# TLE985x register map
Vendor: Infineon Technologies AG; Series: MOTIX MCU; File version: 1.6
CPU: CM0 r0p0, little endian, no MPU, no FPU, 2 interrupt priority bits
Registers are 32-bit, read-write, no defined reset value unless marked. A register's access mark holds for its fields unless they carry their own. Offsets are from the block's base; [hi:lo] are bit positions; {n}, {i} and the like mark numbered series; 'fields as' and 'values as' point back to an identical list.

## ADC1
Base 0x40004000
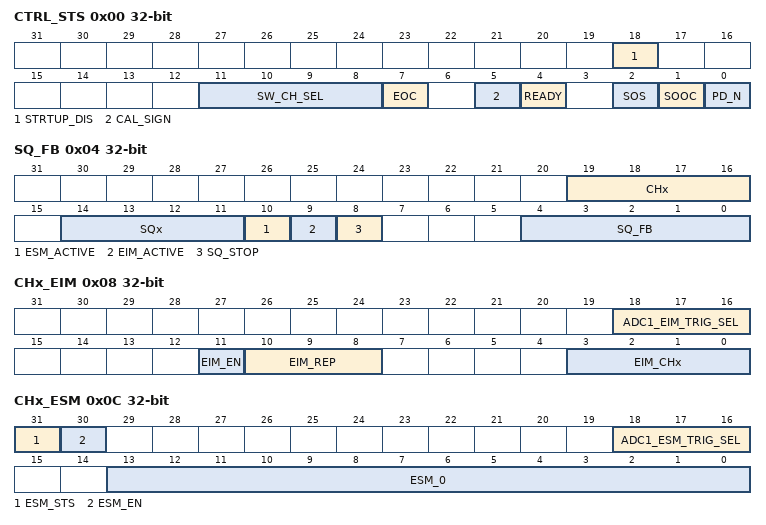
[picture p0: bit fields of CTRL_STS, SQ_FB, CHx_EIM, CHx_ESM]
0x00 CTRL_STS access per field — ADC1 Control and Status Register
  [18] STRTUP_DIS rw — DPP1 Startup Disable
    0=Startup_Enable (DPP1 Startup enabled); 1=Startup_Disable (DPP1 Startup disable)
  [11:8] SW_CH_SEL rw — Channel for software mode
    {v}=CH{v}_EN (Channel {v} enable) (v=0..9); 12=CH12_EN (Channel 12 enable); 13=CH13_EN (Channel 13 enable)
  [7] EOC ro — ADC1 End of Conversion (software mode)
    0=Pending (conversion still running); 1=Finished (conversion has finished)
  [5] CAL_SIGN ro — Output of Comparator to Steer Gain / Offset calibration
  [4] READY ro — HVADC Ready bit
    0=Not_ready (Module in power down or in init phase); 1=Ready (set automatically 5 ADC clock cycles after module is enabled)
  [2] SOS rw — ADC1 Start of Sampling/Conversion (software mode)
    0=Disable (no conversion is started); 1=Enable (conversion is started)
  [1] SOOC rw — ADC1 Start of Offset Calibration (software mode)
    0=Disable (no offset calibration is started); 1=Enable (offset calibration is started)
  [0] PD_N rw — ADC1 Power Down Signal
    0=POWER_DOWN (ADC1 is powered down); 1=ACTIVE (ADC1 is switched on)
0x04 SQ_FB ro — Sequencer Feedback Register
  [19:16] CHx — Current ADC1 Channel
    {v}=CH{v} (Channel {v} enable) (v=0..13)
  [14:11] SQx — Current Active ADC1 Sequence
    {v}=SQ{v} (Sequence {v} enable) (v=0..13)
  [10] ESM_ACTIVE — ADC1 ESM active
    0=not_active (ESM not active); 1=active (ESM active)
  [9] EIM_ACTIVE — ADC1 EIM active
    0=not_active (EIM not active); 1=active (EIM active)
  [8] SQ_STOP — ADC1 Sequencer Stop Signal for DPP
    0=DPP_Running (Postprocessing Sequencer in running mode); 1=DPP_Stopped (Postprocessing Sequencer stopped / Software Mode entered)
  [4:0] SQ_FB — Current Sequence that caused software mode
    {v}=SQ{v} (Sequence {v} enable) (v=0..13); 26=ESM; 28=SUSPEND (SW Mode per Flag)
0x08 CHx_EIM — Channel Setting Bits for Exceptional Interrupt Measurement
  [18:16] ADC1_EIM_TRIG_SEL — Trigger selection for exceptional interrupt measurement (EIM)
    0=NONE; 1=COUT63; 2=GPT12_T6OUT; 3=GPT12_T3OUT; 4=T2 (t2_adc_trigger); 5=T21 (t21_adc_trigger)
  [11] EIM_EN — Exceptional interrupt measurement (EIM) Trigger Event enable
    0=DISABLE (start of EIM disabled); 1=ENABLE (start of IEM enabled)
  [10:8] EIM_REP — Repeat count for exceptional interrupt measurement (EIM)
    0=Continuous Mode; 1=Measurements (2 SOC generated for ADC10); 2=Measurements (4 SOC generated for ADC10); 3=Measurements (8 SOC generated for ADC10); 4=Measurements (16 SOC generated for ADC10); 5=Measurements (32 SOC generated for ADC10); 6=Measurements (64 SOC generated for ADC10); 7=Measurements (128 SOC generated for ADC10)
  [3:0] EIM_CHx — Channel set for exceptional interrupt measurement (EIM)
    values as CTRL_STS.SW_CH_SEL
0x0C CHx_ESM — Channel Setting Bits for Exceptional Sequence Measurement
  [31] ESM_STS — Exceptional Sequence Measurement is finished
    0=not_active (Exceptional Sequence Measurement not done); 1=done (Exceptional Sequence Measurement done)
  [30] ESM_EN — Enable for Exceptional Sequence Measurement Trigger Event
    0=Disable (start of ESM disabled); 1=Enable (start of ESM enabled)
  [18:16] ADC1_ESM_TRIG_SEL — Trigger selection for exceptional sequence measurement (ESM)
    values as CHx_EIM.ADC1_EIM_TRIG_SEL
  [13:0] ESM_0 — Channel Sequence for Exceptional Sequence Measurement (ESM)
    1=CH0_EN (Channel 0 enable); 2=CH1_EN (Channel 1 enable); 4=CH2_EN (Channel 2 enable); 8=CH3_EN (Channel 3 enable); 16=CH4_EN (Channel 4 enable); 32=CH5_EN (Channel 5 enable); 64=CH6_EN (Channel 6 enable); 128=CH7_EN (Channel 7 enable); 0x100=CH8_EN (Channel 8 enable); 0x200=CH9_EN (Channel 9 enable); 0x400=CH10_EN (Channel 10 enable); 0x800=CH11_EN (Channel 11 enable); 0x1000=CH12_EN (Channel 12 enable); 0x2000=CH13_EN (Channel 13 enable)
0x10 MAX_TIME — Maximum Time for Software Mode
  [7:0] MAX_TIME — Maximum Time in Software Mode
    0=min (Software mode is immediately left); 255=max (Software mode is active for 12.75 us)
0x14 CTRL2 — Measurement Unit 1 Control Register 2
  [13:0] CAL_EN — Calibration Enable for Channels 0 to 13
    1=CH0_EN (Channel 0 calibration enable); 2=CH1_EN (Channel 1 calibration enable); 4=CH2_EN (Channel 2 calibration enable); 8=CH3_EN (Channel 3 calibration enable); 16=CH4_EN (Channel 4 calibration enable); 32=CH5_EN (Channel 5 calibration enable); 64=CH6_EN (Channel 6 calibration enable); 128=CH7_EN (Channel 7 calibration enable); 0x100=CH8_EN (Channel 8 calibration enable); 0x200=CH9_EN (Channel 9 calibration enable); 0x400=CH10_EN (Channel 10 calibration enable); 0x800=CH11_EN (Channel 11 calibration enable); 0x1000=CH12_EN (Channel 12 calibration enable); 0x2000=CH13_EN (Channel 13 calibration enable)
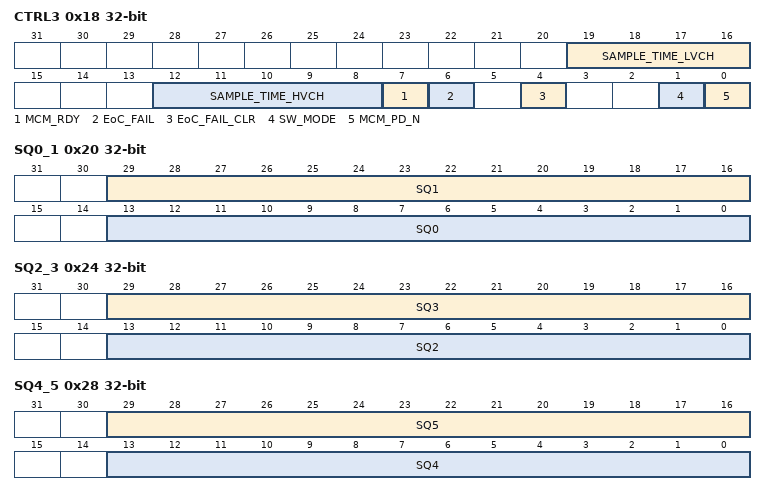
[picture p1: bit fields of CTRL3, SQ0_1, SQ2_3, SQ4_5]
0x18 CTRL3 access per field — Measurement Unit 1 Control Register 3
  [19:16] SAMPLE_TIME_LVCH rw — Sample time of ADC1
    0=ADCCLK4 (4 ADC_CLK clock periods); 1=ADCCLK6 (6 ADC_CLK clock periods); 2=ADCCLK8 (8 ADC_CLK clock periods(default)); 3=ADCCLK10 (10 ADC_CLK clock periods); 4=ADCCLK12 (12 ADC_CLK clock periods); 5=ADCCLK14 (14 ADC_CLK clock periods); 6=ADCCLK16 (16 ADC_CLK clock periods); 7=ADCCLK18 (18 ADC_CLK clock periods); 8=ADCCLK20 (20 ADC_CLK clock periods); 9=ADCCLK22 (22 ADC_CLK clock periods)
  [12:8] SAMPLE_TIME_HVCH rw — Sample time of ADC1
    0=ADCCLK4 (4 ADC_CLK clock periods); 1=ADCCLK6 (6 ADC_CLK clock periods); 2=ADCCLK8 (8 ADC_CLK clock periods); 3=ADCCLK10 (10 ADC_CLK clock periods); 4=ADCCLK12 (12 ADC_CLK clock periods); 5=ADCCLK14 (14 ADC_CLK clock periods); 6=ADCCLK16 (16 ADC_CLK clock periods); 7=ADCCLK18 (18 ADC_CLK clock periods); 8=ADCCLK20 (20 ADC_CLK clock periods); 9=ADCCLK22 (22 ADC_CLK clock periods); 10=ADCCLK24 (24 ADC_CLK clock periods (default)); 11=ADCCLK26 (26 ADC_CLK clock periods); 12=ADCCLK28 (28 ADC_CLK clock periods); 13=ADCCLK30 (30 ADC_CLK clock periods); 14=ADCCLK32 (32 ADC_CLK clock periods); 15=ADCCLK34 (34 ADC_CLK clock periods); 16=ADCCLK36 (36 ADC_CLK clock periods); 17=ADCCLK38 (38 ADC_CLK clock periods); 18=ADCCLK40 (40 ADC_CLK clock periods); 19=ADCCLK42 (42 ADC_CLK clock periods); 20=ADCCLK44 (44 ADC_CLK clock periods); 21=ADCCLK46 (46 ADC_CLK clock periods); 22=ADCCLK48 (48 ADC_CLK clock periods); 23=ADCCLK50 (50 ADC_CLK clock periods); 24=ADCCLK52 (52 ADC_CLK clock periods); 25=ADCCLK54 (54 ADC_CLK clock periods); 26=ADCCLK56 (56 ADC_CLK clock periods); 27=ADCCLK58 (58 ADC_CLK clock periods); 28=ADCCLK60 (60 ADC_CLK clock periods); 29=ADCCLK62 (62 ADC_CLK clock periods)
  [7] MCM_RDY ro — Ready Signal for MCM after Power On or Reset
    0=MCM_Not_Ready (Measurement Core Module in startup phase); 1=MCM_Ready (Measurement Core Module start-up phase finished)
  [6] EoC_FAIL rw — Fail of ADC End of Conversion Signal
    0=ADC_EoC_available (End of Conversion Signal was sent properly by ADC); 1=ADC_EoC_not_available (End of Conversion Signal was not sent properly by ADC)
  [4] EoC_FAIL_CLR wo — Fail of ADC End of Conversion Signal Clear
    0=ADC_EoC_Fail_not_clear (no clear of EoC_FAIL flag); 1=ADC_EoC_Fail_clear (Clear of EoC_FAIL flag)
  [1] SW_MODE rw — Flag to enter SW Mode
    0=Software_Mode_Disable (Sequencer running); 1=Software_Mode_Enabled (Sequencer stopped)
  [0] MCM_PD_N rw — Power Down Signal for MCM
    0=MCM_Disabled (Measurement Core Module Disabled); 1=MCM_Enabled (Measurement Core Module Enabled)
0x1C CTRL5 — Measurement Unit 1 Control Register 5
  [13:0] FILT_OUT_SEL_13_0 — Output Filter Selection for Channels 0 to 13
0x20 SQ0_1 — Measurement Unit 1 Channel Enable Bits for Cycle 0-1
  [29:16] SQ1 — Sequence 1 channel enable
  [13:0] SQ0 — Sequence 0 channel enable
0x24 SQ2_3 — Measurement Unit 1 Channel Enable Bits for Cycle 2-3
  [29:16] SQ3 — Sequence 3 channel enable
  [13:0] SQ2 — Sequence 2 channel enable
0x28 SQ4_5 — Measurement Unit 1 Channel Enable Bits for Cycle 4-5
  [29:16] SQ5 — Sequence 5 channel enable
  [13:0] SQ4 — Sequence 4 channel enable
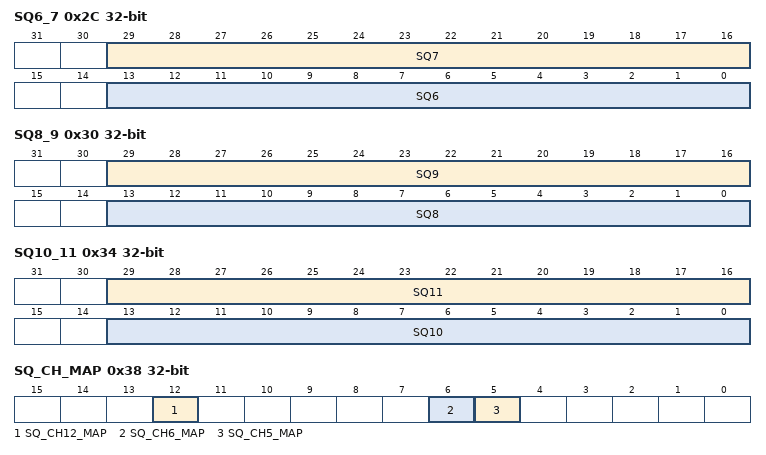
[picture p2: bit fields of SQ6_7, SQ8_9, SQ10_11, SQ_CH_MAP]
0x2C SQ6_7 — Measurement Unit 1 Channel Enable Bits for Cycle 6-7
  [29:16] SQ7 — Sequence 7 channel enable
  [13:0] SQ6 — Sequence 6 channel enable
0x30 SQ8_9 — Measurement Unit 1 Channel Enable Bits for Cycle 8-9
  [29:16] SQ9 — Sequence 9 channel enable
  [13:0] SQ8 — Sequence 8 channel enable
0x34 SQ10_11 — Measurement Unit 1 Channel Enable Bits for Cycle 10-11
  [29:16] SQ11 — Sequence 11 channel enable
  [13:0] SQ10 — Sequence 10 channel enable
0x38 SQ_CH_MAP — ADC1 Channel Mapping for Sequencer
  [12] SQ_CH12_MAP — ADC mapping to CH12
    0=P2_7 (P2.7 mapped to CH12); 1=P2_4 (P2.4 mapped to CH12)
  [6] SQ_CH6_MAP — ADC mapping to CH6
    0=P2_0 (P2.0 mapped to CH6); 1=P2_8 (P2.8 mapped to CH6)
  [5] SQ_CH5_MAP — ADC mapping to CH5
    0=MON4 (MON4 mapped to CH5); 1=MON5 (MON5 mapped to CH5)
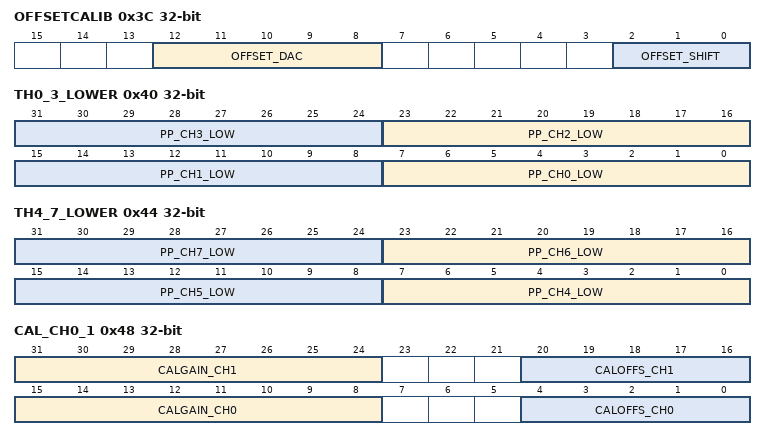
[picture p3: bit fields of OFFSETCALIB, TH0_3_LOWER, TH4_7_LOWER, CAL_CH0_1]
0x3C OFFSETCALIB — ADC1 Offset Calibration Register
  [12:8] OFFSET_DAC — Set the Value of the Offset Calibration DAC
  [2:0] OFFSET_SHIFT — Set the Value of the Offset Shift DAC
0x40 TH0_3_LOWER — Lower Comparator Trigger Level Post-Processing-Channel 0-3
  [8n+7:8n] PP_CH{n}_LOW (n=0..3) — Post-Processing-Channel {n} lower trigger level
0x44 TH4_7_LOWER — Lower Comparator Trigger Level Post-Processing-Channel 4-7
  [8n-25:8n-32] PP_CH{n}_LOW (n=4..7) — Post-Processing-Channel {n} lower trigger level
0x48 CAL_CH0_1 — Calibration for Channel 0 and 1
  [31:24] CALGAIN_CH1 — Gain Calibration for channel 1
  [20:16] CALOFFS_CH1 — Offset Calibration for channel 1
  [15:8] CALGAIN_CH0 — Gain Calibration for channel 0
  [4:0] CALOFFS_CH0 — Offset Calibration for channel 0
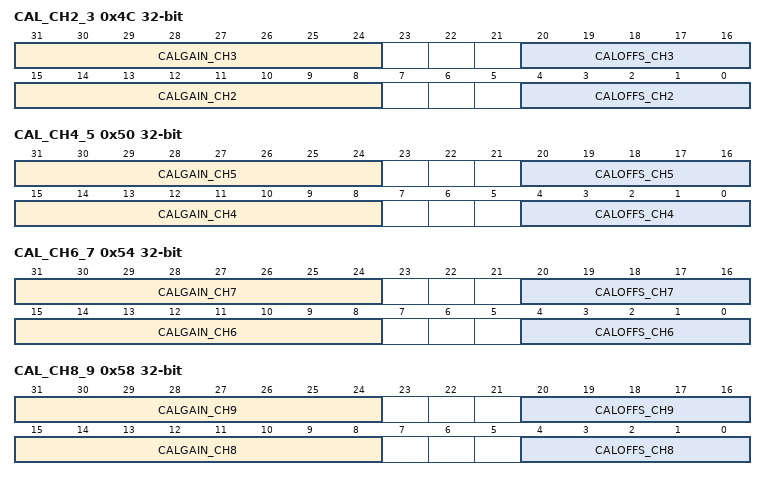
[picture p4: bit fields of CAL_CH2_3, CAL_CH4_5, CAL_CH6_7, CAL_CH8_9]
0x4C CAL_CH2_3 — Calibration for Channel 2 and 3
  [31:24] CALGAIN_CH3 — Gain Calibration for channel 3
  [20:16] CALOFFS_CH3 — Offset Calibration for channel 3
  [15:8] CALGAIN_CH2 — Gain Calibration for channel 2
  [4:0] CALOFFS_CH2 — Offset Calibration for channel 2
0x50 CAL_CH4_5 — Calibration for Channel 4 and 5
  [31:24] CALGAIN_CH5 — Gain Calibration for channel 5
  [20:16] CALOFFS_CH5 — Offset Calibration for channel 5
  [15:8] CALGAIN_CH4 — Gain Calibration for channel 4
  [4:0] CALOFFS_CH4 — Offset Calibration for channel 4
0x54 CAL_CH6_7 — Calibration for Channel 6 and 7
  [31:24] CALGAIN_CH7 — Gain Calibration for channel 7
  [20:16] CALOFFS_CH7 — Offset Calibration for channel 7
  [15:8] CALGAIN_CH6 — Gain Calibration for channel 6
  [4:0] CALOFFS_CH6 — Offset Calibration for channel 6
0x58 CAL_CH8_9 — Calibration for Channel 8 and 9
  [31:24] CALGAIN_CH9 — Gain Calibration for channel 9
  [20:16] CALOFFS_CH9 — Offset Calibration for channel 9
  [15:8] CALGAIN_CH8 — Gain Calibration for channel 8
  [4:0] CALOFFS_CH8 — Offset Calibration for channel 8
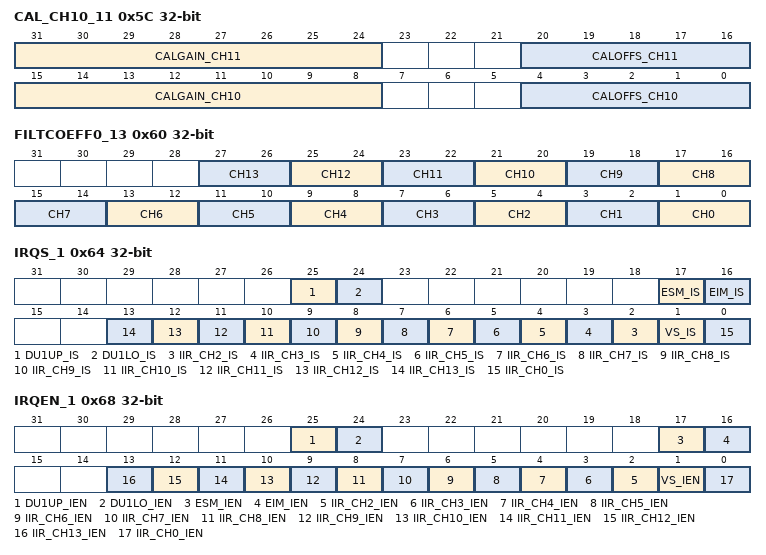
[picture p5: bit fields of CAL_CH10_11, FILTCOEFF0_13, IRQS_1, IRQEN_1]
0x5C CAL_CH10_11 — Calibration for Channel 10 and 11
  [31:24] CALGAIN_CH11 — Gain Calibration for channel 11
  [20:16] CALOFFS_CH11 — Offset Calibration for channel 11
  [15:8] CALGAIN_CH10 — Gain Calibration for channel 10
  [4:0] CALOFFS_CH10 — Offset Calibration for channel 10
0x60 FILTCOEFF0_13 — Filter Coefficients Measurement Unit Channel 0-13
  [all] fields
    0=1divBy2 (weight of current sample); 1=1divBy4 (weight of current sample); 2=1divBy8 (weight of current sample); 3=1divBy16 (weight of current sample)
  [2n+1:2n] CH{n} (n=0..13) — Filter Coefficients ADC channel {n}
0x64 IRQS_1 — ADC1 Interrupt Status 1 Register
  [25] DU1UP_IS — ADC1 Differential Unit 1 (DU1) upper Channel Interrupt Status
    0=INACTIVE (No DU upper Channel Interrupt has occurred); 1=ACTIVE (DU upper Channel Interrupt has occurred)
  [24] DU1LO_IS — ADC1 Differential Unit 1 (DU1) lower Channel Interrupt Status
    0=INACTIVE (No DU lower Channel Interrupt has occurred); 1=ACTIVE (DU lower Channel Interrupt has occurred)
  [17] ESM_IS — Exceptional Sequence Measurement (ESM) Status
    0=INACTIVE (No ESM has occurred); 1=ACTIVE (ESM occurred)
  [16] EIM_IS — Exceptional Interrupt Measurement (EIM) Status
    0=INACTIVE (No EIM occurred); 1=ACTIVE (EIM occurred)
  [n] IIR_CH{n}_IS (n=2..13) — ADC1 IIR-Filter-Channel {n} Interrupt Status
    0=INACTIVE (No Channel {n} Interrupt has occurred); 1=ACTIVE (Channel {n} Interrupt has occurred)
  [1] VS_IS — ADC1 IIR-Filter-Channel 1 Interrupt Status
    0=INACTIVE (No Channel 1 Interrupt has occurred); 1=ACTIVE (Channel 1 Interrupt has occurred)
  [0] IIR_CH0_IS — ADC1 IIR-Filter-Channel 0 Interrupt Status
    0=INACTIVE (No Channel 0 Interrupt has occurred); 1=ACTIVE (Channel 0 Interrupt has occurred)
0x68 IRQEN_1 — ADC1 Interrupt Enable 1 Register
  [all] fields
    0=DISABLED (Interrupt disabled); 1=ENABLED (Interrupt enabled)
  [25] DU1UP_IEN — Differential Unit 1 upper Interrupt Enable
  [24] DU1LO_IEN — Differential Unit 1 lower Interrupt Enable
  [17] ESM_IEN — Exceptional Sequence Measurement (ESM) Interrupt Enable
  [16] EIM_IEN — Exceptional Interrupt Measurement (EIM) Interrupt Enable
  [n] IIR_CH{n}_IEN (n=2..13) — ADC1 IIR-Filter-Channel {n} Interrupt Enable
  [1] VS_IEN — ADC1 IIR-Filter-Channel 1 Interrupt Enable
  [0] IIR_CH0_IEN — ADC1 IIR-Filter-Channel 0 Interrupt Enable
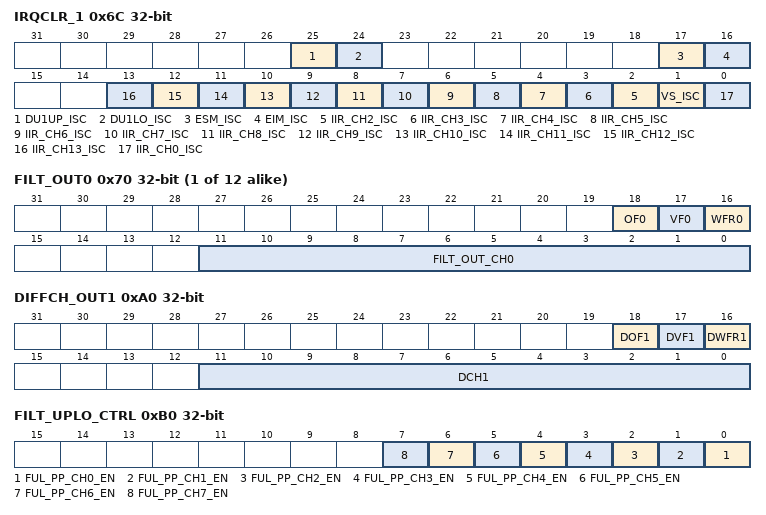
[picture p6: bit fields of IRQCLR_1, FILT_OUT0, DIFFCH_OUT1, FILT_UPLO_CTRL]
0x6C IRQCLR_1 wo — ADC1 Interrupt Status Clear 1 Register
  [25] DU1UP_ISC — Differential Unit 1 lower Interrupt Status Clear
    0=INACTIVE (interrupt status is not cleared); 1=ACTIVE (interrupt status is cleared)
  [24] DU1LO_ISC — Differential Unit 1 lower Interrupt Status Clear
    values as DU1UP_ISC
  [17] ESM_ISC — Exceptional Sequence Measurement (ESM) Status Clear
    0=INACTIVE (No ESM has cleared); 1=ACTIVE (ESM cleared)
  [16] EIM_ISC — Exceptional Interrupt Measurement (EIM) Status Clear
    0=INACTIVE (No EIM cleared); 1=ACTIVE (EIM cleared)
  [n] IIR_CH{n}_ISC (n=2..13) — ADC1 IIR-Filter-Channel {n} Interrupt Status Clear
    values as DU1UP_ISC
  [1] VS_ISC — ADC1 IIR-Filter-Channel 1 Interrupt Status Clear
    values as DU1UP_ISC
  [0] IIR_CH0_ISC — ADC1 IIR-Filter-Channel 0 Interrupt Status Clear
    values as DU1UP_ISC
{0x70+4i} FILT_OUT{i} access per field (i=0..11) — ADC1 or Filter Output Channel {i}
  [18] OF{i} ro — Overrun Flag
    0=NO_OVERRUN (Result register not overwritten); 1=OVERRUN (Result register overwritten)
  [17] VF{i} ro — Valid Flag
    0=NOT_VALID (No new valid data available); 1=VALID (Result register contains valid data and has not yet been read)
  [16] WFR{i} rw — Wait for Read Mode
    0=DISABLE (overwrite mode); 1=ENABLE (wait for read mode enabled)
  [11:0] FILT_OUT_CH{i} ro — ADC or filter output value channel {i}
0xA0 DIFFCH_OUT1 access per field — ADC1 Differential Channel Output 1
  [18] DOF1 ro — Overrun Flag
    values as FILT_OUT0.OF{i}
  [17] DVF1 ro — Valid Flag
    values as FILT_OUT0.VF{i}
  [16] DWFR1 rw — Wait for Read Mode
    values as FILT_OUT0.WFR{i}
  [11:0] DCH1 ro — ADC differential output value 1
0xB0 FILT_UPLO_CTRL — Upper And Lower Threshold Filter Enable
  [all] fields
    0=Disable; 1=Enable
  [n] FUL_PP_CH{n}_EN (n=0..7) — Upper and lower threshold IIR filter enable Post-Processing-Channel {n}
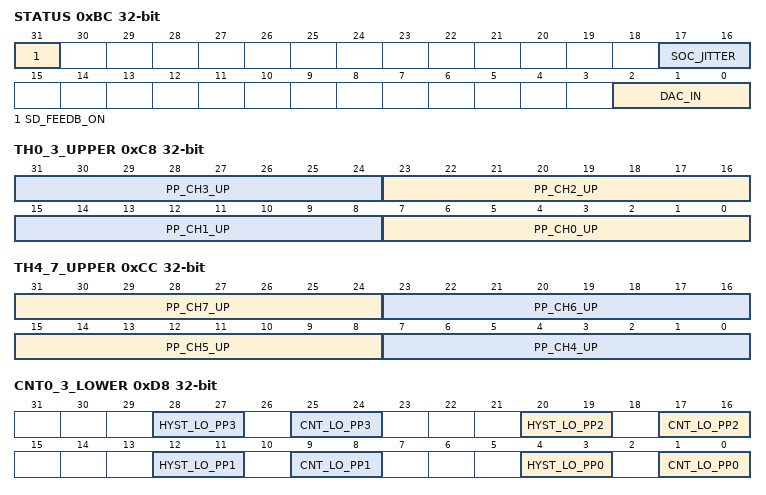
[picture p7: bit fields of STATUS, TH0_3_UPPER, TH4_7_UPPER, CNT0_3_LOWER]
0xBC STATUS — ADC1 Status Register
  [31] SD_FEEDB_ON — Sigma Delta Feedback Loop
    0=Disable; 1=Enable
  [17:16] SOC_JITTER — Programs Soc Clock Jitter
    0=0n; 1=3_5n; 2=5_5n; 3=8n
  [2:0] DAC_IN — Programs the 2-bit DAC for functional test
    {v}=added {v} LSB (v=0..3)
0xC4 DCHTH1_4_LOWER — Lower Comparator Trigger Level Differential Channel 1
  [7:0] DCH1_LOW — Differential Channel 1 lower trigger level
0xC8 TH0_3_UPPER — Upper Comparator Trigger Level Post-Processing-Channel 0-3
  [8n+7:8n] PP_CH{n}_UP (n=0..3) — Post-Processing-Channel {n} upper trigger level
0xCC TH4_7_UPPER — Upper Comparator Trigger Level Post-Processing-Channel 4-7
  [31:24] PP_CH7_UP — Post-Processing-Channel 7 upper trigger level
  [23:16] PP_CH6_UP — Post-Processing-Channel 6upper trigger level
  [15:8] PP_CH5_UP — Post-Processing-Channel 5 upper trigger level
  [7:0] PP_CH4_UP — Post-Processing-Channel 4 upper trigger level
0xD4 DCHTH1_4_UPPER — Upper Comparator Trigger Level Differential Channel 1
  [7:0] DCH1_UP — Differential Channel 1 upper trigger level
0xD8 CNT0_3_LOWER — Lower Counter Trigger Level Post-Processing-Channel 0-3
  [8n+4:8n+3] HYST_LO_PP{n} (n=0..3) — Post-Processing-Channel {n} lower hysteresis
    0=HYSTOFF (hysteresis switched off); 1=HYST4 (hysteresis = 4); 2=HYST8 (hysteresis = 8); 3=HYST16 (hysteresis = 16)
  [8n+1:8n] CNT_LO_PP{n} (n=0..3) — Lower timer trigger threshold Post-Processing-Channel {n}
    0=1 measurement; 1=2 measurements; 2=4 measurements; 3=7 measurements
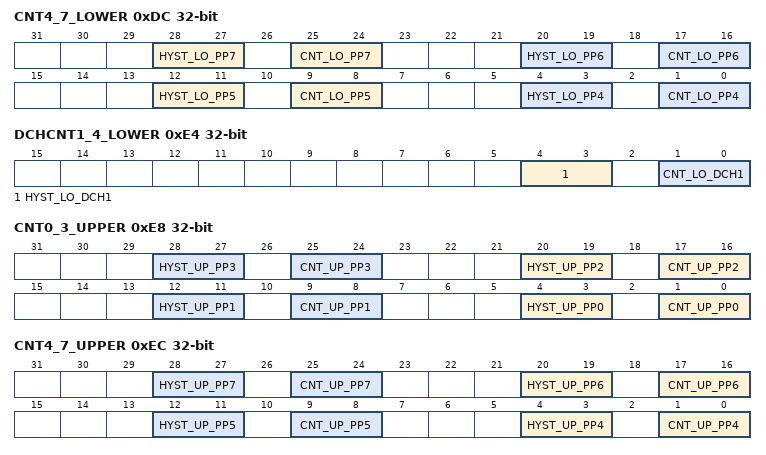
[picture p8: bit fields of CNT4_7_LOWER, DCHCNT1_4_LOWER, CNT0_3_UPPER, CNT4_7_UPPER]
0xDC CNT4_7_LOWER — Lower Counter Trigger Level Post-Processing-Channel 4-7
  [28:27] HYST_LO_PP7 — Post-Processing-Channel 7 lower hysteresis
    values as CNT0_3_LOWER.HYST_LO_PP0
  [8n-31:8n-32] CNT_LO_PP{n} (n=4..7) — Lower timer trigger threshold Post-Processing-Channel {n}
    values as CNT0_3_LOWER.CNT_LO_PP0
  [20:19] HYST_LO_PP6 — Channel 6 lower hysteresis
    values as CNT0_3_LOWER.HYST_LO_PP0
  [12:11] HYST_LO_PP5 — Post-Processing-Channel 5 lower hysteresis
    values as CNT0_3_LOWER.HYST_LO_PP0
  [4:3] HYST_LO_PP4 — Post-Processing-Channel 4 lower hysteresis
    values as CNT0_3_LOWER.HYST_LO_PP0
0xE4 DCHCNT1_4_LOWER — Lower Counter Trigger Level DifferentialChannel 1
  [4:3] HYST_LO_DCH1 — Post-Processing-Channel 4 lower hysteresis
    values as CNT0_3_LOWER.HYST_LO_PP0
  [1:0] CNT_LO_DCH1 — Lower timer trigger threshold Post-Processing-Channel 4
    values as CNT0_3_LOWER.CNT_LO_PP0
0xE8 CNT0_3_UPPER — Upper Counter Trigger Level Post-Processing-Channel 0-3
  [8n+4:8n+3] HYST_UP_PP{n} (n=0..3) — Post-Processing-Channel {n} upper hysteresis
    values as CNT0_3_LOWER.HYST_LO_PP0
  [8n+1:8n] CNT_UP_PP{n} (n=0..3) — Upper timer trigger threshold Post-Processing-Channel {n}
    values as CNT0_3_LOWER.CNT_LO_PP0
0xEC CNT4_7_UPPER — Upper Counter Trigger Level Post-Processing-Channel 4-7
  [8n-28:8n-29] HYST_UP_PP{n} (n=4..7) — Post-Processing-Channel {n} upper hysteresis
    values as CNT0_3_LOWER.HYST_LO_PP0
  [8n-31:8n-32] CNT_UP_PP{n} (n=4..7) — Upper timer trigger threshold Post-Processing-Channel {n}
    values as CNT0_3_LOWER.CNT_LO_PP0
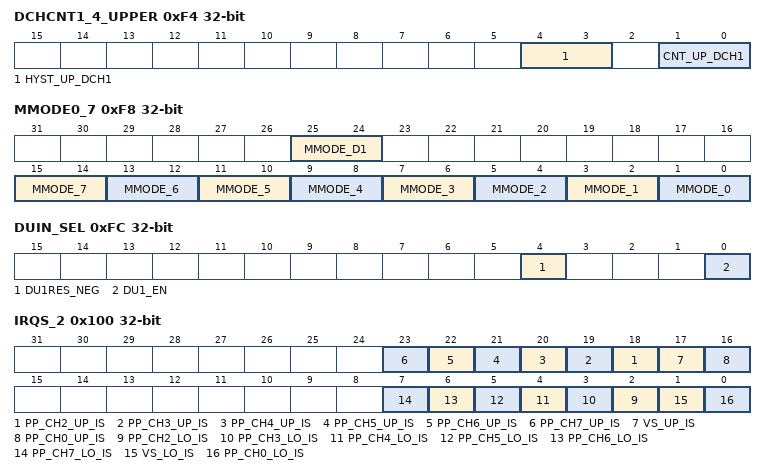
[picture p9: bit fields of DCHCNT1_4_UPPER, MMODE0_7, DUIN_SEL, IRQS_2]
0xF4 DCHCNT1_4_UPPER — Upper Counter Trigger Level DifferentialChannel 1
  [4:3] HYST_UP_DCH1 — Post-Processing-Channel 4 upper hysteresis
    values as CNT0_3_LOWER.HYST_LO_PP0
  [1:0] CNT_UP_DCH1 — Upper timer trigger threshold Post-Processing-Channel 4
    values as CNT0_3_LOWER.CNT_LO_PP0
0xF8 MMODE0_7 — Overvoltage Measurement Mode of Post-Processing-Channel 0-7
  [all] fields
    0=MMODE0 (upper and lower voltage/limit measurement); 1=MMODEUV (undervoltage/-limit measurement); 2=MMODEOV (overvoltage/-limit measurement)
  [25:24] MMODE_D1 — Measurement mode Differential Channel 1
  [2n+1:2n] MMODE_{n} (n=0..7) — Measurement mode Post-Processing-Channel {n}
0xFC DUIN_SEL access per field — Measurement Unit 1 - Differential Unit Input Selection Register
  [4] DU1RES_NEG ro — Differential Unit 1 result negative
    0=DU1_Result_positive (Differential Unit 1 result positive after calculation); 1=DU1_Result_negative (Differential Unit 1 result negative after calculation)
  [0] DU1_EN rw — Differential Unit 1 enable
    0=DU1_disable (Differential Unit 1 is disabled); 1=DU1_enable (Differential Unit 1 is enabled)
0x100 IRQS_2 — ADC1 Interrupt Status 2 Register
  [all] fields
    0=INACTIVE (no interrupt has occurred); 1=ACTIVE (interrupt has occurred)
  [n+16] PP_CH{n}_UP_IS (n=2..7) — ADC1 Post-Processing-Channel {n} Upper Threshold Interrupt Status
  [17] VS_UP_IS — ADC1 Post-Processing-Channel 1 Upper Threshold Interrupt Status
  [16] PP_CH0_UP_IS — ADC1 Post-Processing-Channel 0 Upper Threshold Interrupt Status
  [n] PP_CH{n}_LO_IS (n=2..7) — ADC1 Post-Processing-Channel {n} Lower Threshold Interrupt Status
  [1] VS_LO_IS — ADC1 Post-Processing-Channel 1 Lower Threshold Interrupt Status
  [0] PP_CH0_LO_IS — ADC1 Post-Processing-Channel 0 Lower Threshold Interrupt Status
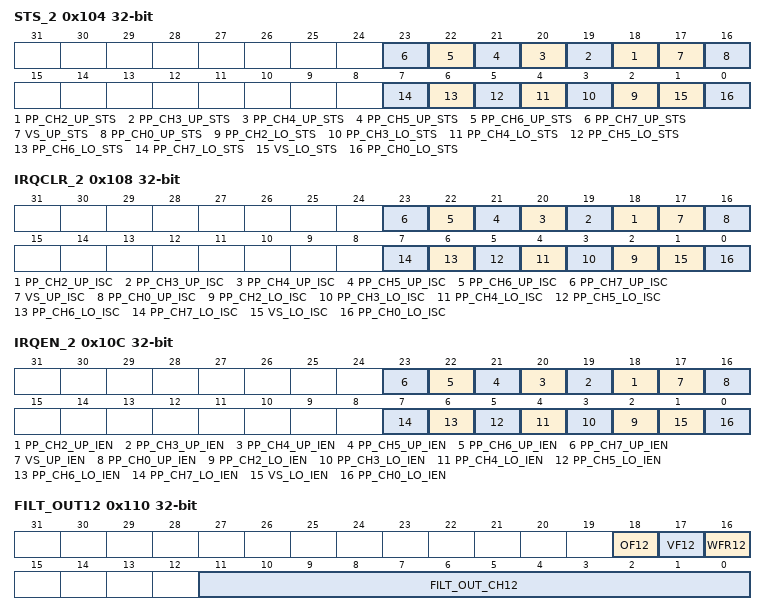
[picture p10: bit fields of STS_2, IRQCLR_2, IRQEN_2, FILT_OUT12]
0x104 STS_2 ro — ADC1 Status 2 Register
  [all] fields
    0=Below_limit (Status below upper threshold); 1=Above_limit (Upper threshold exceeded)
  [n+16] PP_CH{n}_UP_STS (n=2..7) — ADC1 Post-Processing-Channel {n} Upper Threshold Status
  [17] VS_UP_STS — ADC1 Post-Processing-Channel 1 Upper Threshold Status
  [16] PP_CH0_UP_STS — ADC1 Post-Processing-Channel 0 Upper Threshold Status
  [n] PP_CH{n}_LO_STS (n=2..7) — ADC1 Post-Processing-Channel {n} Lower Threshold Status
  [1] VS_LO_STS — ADC1 Post-Processing-Channel 1 Lower Threshold Status
  [0] PP_CH0_LO_STS — ADC1 Post-Processing-Channel 0 Lower Threshold Status
0x108 IRQCLR_2 wo — ADC1 Interrupt Status Clear 2 Register
  [all] fields
    values as IRQCLR_1.DU1UP_ISC
  [n+16] PP_CH{n}_UP_ISC (n=2..7) — ADC1 Post-Processing-Channel {n} Upper Threshold Interrupt Status Clear
  [17] VS_UP_ISC — ADC1 Post-Processing-Channel 1 Upper Threshold Interrupt Status Clear
  [16] PP_CH0_UP_ISC — ADC1 Post-Processing-Channel 0 Upper Threshold Interrupt Status Clear
  [n] PP_CH{n}_LO_ISC (n=2..7) — ADC1 Post-Processing-Channel {n} Lower Threshold Interrupt Status Clear
  [1] VS_LO_ISC — ADC1 Post-Processing-Channel 1 Lower Threshold Interrupt Status Clear
  [0] PP_CH0_LO_ISC — ADC1 Post-Processing-Channel 0 Lower Threshold Interrupt Status Clear
0x10C IRQEN_2 — ADC1 Interrupt Enable 2 Register
  [all] fields
    values as the fields of IRQEN_1
  [n+16] PP_CH{n}_UP_IEN (n=2..7) — ADC1 Post-Processing-Channel {n} Upper Threshold Interrupt Enable
  [17] VS_UP_IEN — ADC1 Post-Processing-Channel 1 Upper Threshold Interrupt Enable
  [16] PP_CH0_UP_IEN — ADC1 Post-Processing-Channel 0 Upper Threshold Interrupt Enable
  [n] PP_CH{n}_LO_IEN (n=2..7) — ADC1 Post-Processing-Channel {n} Lower Threshold Interrupt Enable
  [1] VS_LO_IEN — ADC1 Post-Processing-Channel 1 Lower Threshold Interrupt Enable
  [0] PP_CH0_LO_IEN — ADC1 Post-Processing-Channel 0 Lower Threshold Interrupt Enable
0x110 FILT_OUT12 access per field — ADC1 or Filter Output Channel 12
  [18] OF12 ro — Overrun Flag
    values as FILT_OUT0.OF{i}
  [17] VF12 ro — Valid Flag
    values as FILT_OUT0.VF{i}
  [16] WFR12 rw — Wait for Read Mode
    values as FILT_OUT0.WFR{i}
  [11:0] FILT_OUT_CH12 ro — ADC or filter output value channel 12
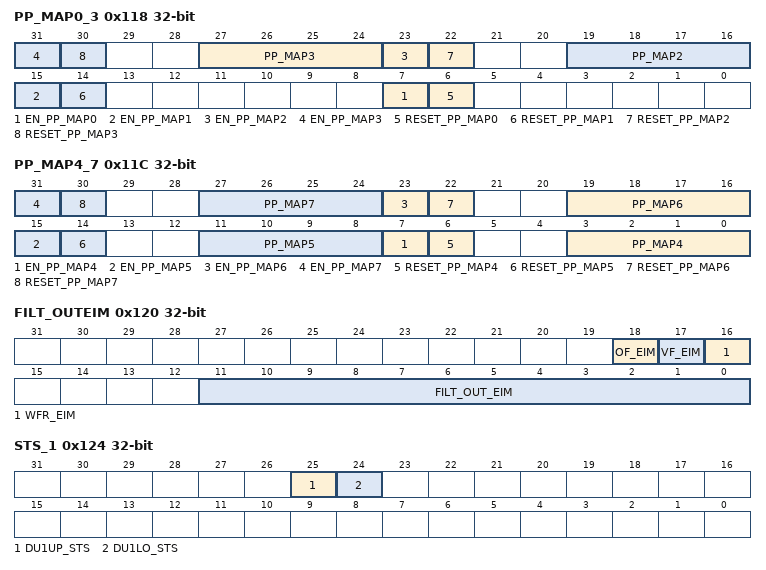
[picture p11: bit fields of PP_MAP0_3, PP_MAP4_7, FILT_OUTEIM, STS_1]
0x118 PP_MAP0_3 — Post-Processing Mapping Channel 0-3
  [8n+7] EN_PP_MAP{n} (n=0..3) — Mapping Enable for Post-Processing-Channel {n}
    0=Disabled (Mapping Disabled); 1=Enabled (Mapping Enabled)
  [8n+6] RESET_PP_MAP{n} (n=0..3) — Post-Processing Reset for Mapped Post-Processing-Channel {n}
    0=Running (Post-Processing running); 1=Reset (Post-Processing reset)
  [27:24] PP_MAP3 — Mapping of Entry Channel to Post-Processing-Channel 3
    0=Ch0 (Entry Channel 0); 13=Ch13 (Entry Channel 13)
  [19:16] PP_MAP2 — Mapping of Entry Channel to Post-Processing-Channel 2
    0=Ch0 (Entry Channel 0); 13=Ch13 (Entry Channel 13)
0x11C PP_MAP4_7 — Post-Processing Mapping Channel 4-7
  [8n-25] EN_PP_MAP{n} (n=4..7) — Mapping Enable for Post-Processing-Channel {n}
    0=Disabled (Mapping Disabled); 1=Enabled (Mapping Enabled)
  [8n-26] RESET_PP_MAP{n} (n=4..7) — Post-Processing Reset for Mapped Post-Processing-Channel {n}
    values as PP_MAP0_3.RESET_PP_MAP0
  [8n-29:8n-32] PP_MAP{n} (n=4..7) — Mapping of Entry Channel to Post-Processing-Channel {n}
    0=Ch0 (Entry Channel 0); 13=Ch13 (Entry Channel 13)
0x120 FILT_OUTEIM access per field — ADC1 or Filter Output of EIM
  [18] OF_EIM ro — Overrun Flag
    values as FILT_OUT0.OF{i}
  [17] VF_EIM ro — Valid Flag
    values as FILT_OUT0.VF{i}
  [16] WFR_EIM rw — Wait for Read Mode
    values as FILT_OUT0.WFR{i}
  [11:0] FILT_OUT_EIM ro — ADC or filter output value for last EIM measurement
0x124 STS_1 — ADC1 Status 1Register
  [25] DU1UP_STS — ADC1 Differential Unit 1 (DU1) upper Channel Status
    0=INACTIVE (No DU upper Channel Status has occurred); 1=ACTIVE (DU upper Channel Status has occurred)
  [24] DU1LO_STS — ADC1 Differential Unit 1 (DU1) lower Channel Status
    0=INACTIVE (No DU lower Channel Status has occurred); 1=ACTIVE (DU lower Channel Status has occurred)
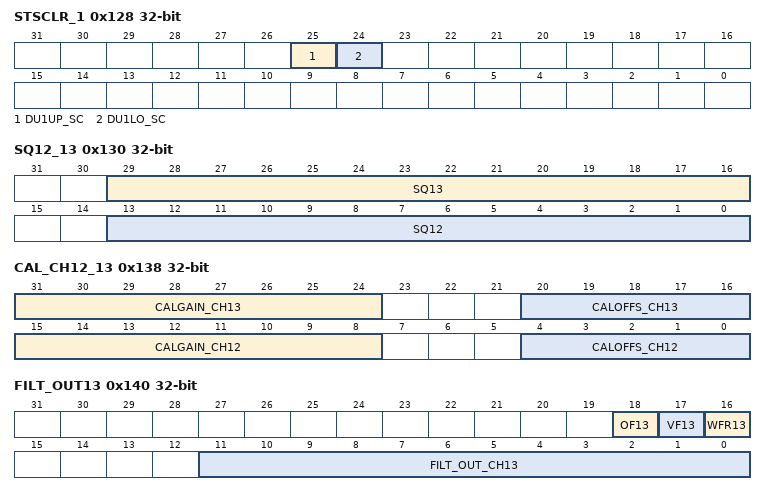
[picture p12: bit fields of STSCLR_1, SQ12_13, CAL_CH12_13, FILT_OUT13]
0x128 STSCLR_1 wo — ADC1 Status Clear 1 Register
  [25] DU1UP_SC — ADC1 Differential Unit 1 (DU1) upper Channel Status Clear
    values as STS_1.DU1UP_STS
  [24] DU1LO_SC — ADC1 Differential Unit 1 (DU1) lower Channel Status Clear
    values as STS_1.DU1LO_STS
0x130 SQ12_13 — Measurement Unit 1 Channel Enable Bits for Cycle 12-13
  [29:16] SQ13 — Sequence 13 channel enable
  [13:0] SQ12 — Sequence 12 channel enable
0x138 CAL_CH12_13 — Calibration for Channel 12 and 13
  [31:24] CALGAIN_CH13 — Gain Calibration for channel 13
  [20:16] CALOFFS_CH13 — Offset Calibration for channel 13
  [15:8] CALGAIN_CH12 — Gain Calibration for channel 12
  [4:0] CALOFFS_CH12 — Offset Calibration for channel 12
0x140 FILT_OUT13 access per field — ADC1 or Filter Output Channel 13
  [18] OF13 ro — Overrun Flag
    values as FILT_OUT0.OF{i}
  [17] VF13 ro — Valid Flag
    values as FILT_OUT0.VF{i}
  [16] WFR13 rw — Wait for Read Mode
    values as FILT_OUT0.WFR{i}
  [11:0] FILT_OUT_CH13 ro — ADC or filter output value channel 13
